# SN32F400 register map
Vendor: SONiX Technology Co., Ltd.; Series: SN32F400; File version: 1.1
CPU: CM0 r0p0, little endian, no MPU, no FPU, 2 interrupt priority bits
Registers are 32-bit, read-write, reset 0x0 unless marked. A register's access mark holds for its fields unless they carry their own. Offsets are from the block's base; [hi:lo] are bit positions.

## SN_FOC — BLDC FOC Function
Base 0x40074000
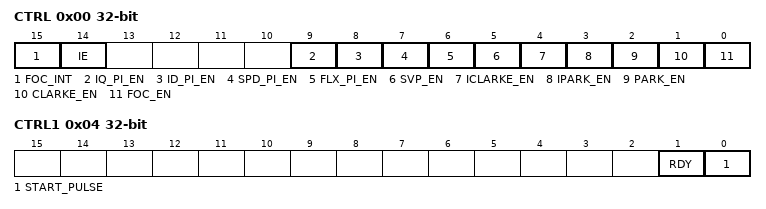
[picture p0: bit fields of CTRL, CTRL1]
0x00 CTRL — Offset:0x00 FOC Control register
  [15] FOC_INT — FOC interrupt
    0=None (No FOC interrupt); 1=Meet (FOC interrupt is triggered)
  [14] IE — FOC interrupt enable bit
    0=Disable FOC interrupt; 1=Enable FOC interrupt
  [9] IQ_PI_EN — Current Q PI function enable bit
    0=Disable current Q PI function; 1=Enable current Q PI function
  [8] ID_PI_EN — Current D PI function enable bit
    0=Disable current D PI function; 1=Enable current D PI function
  [7] SPD_PI_EN — Speed PI function enable bit
    0=Disable speed PI function; 1=Enable speed PI function
  [6] FLX_PI_EN — Flux PI function enable bit
    0=Disable flux PI function; 1=Enable flux PI function
  [5] SVP_EN — SVPWM function enable bit
    0=Disable SVPWM function; 1=Enable SVPWM function
  [4] ICLARKE_EN — IClarke function enable bit
    0=Disable IClarke function; 1=Enable IClarke function
  [3] IPARK_EN — IPark function enable bit
    0=Disable IPark function; 1=Enable IPark function
  [2] PARK_EN — Park function enable bit
    0=Disable Park function; 1=Enable Park function
  [1] CLARKE_EN — Clarke function enable bit
    0=Disable Clarke function; 1=Enable Clarke function
  [0] FOC_EN — FOC enable bit
    0=Disable FOC; 1=Enable FOC
0x04 CTRL1 — Offset:0x04 FOC Control register 1
  [1] RDY ro — FOC ready status
    0=Busy (FOC is operating); 1=Idle (FOC is not operating)
  [0] START_PULSE — FOC operation trigger bit
    0=None (No action); 1=Trigger 1 pulse to start FOC operating
0x08 IA — Offset:0x08 FOC Motor A-phase Current register
  [23:0] IA — Motor A-phase current in I24Q15 format
0x0C IB — Offset:0x0C FOC Motor B-phase Current register
  [23:0] IB — Motor B-phase current in I24Q15 format
0x10 IC — Offset:0x10 FOC Motor C-phase Current register
  [23:0] IC — Motor C-phase current in I24Q15 format
0x14 ANGLE — Offset:0x14 FOC Motor Stator Output Angle register
  [15:0] ANGLE — Motor stator output electrical angle in I24Q15 format
0x18 FLX_CMD — Offset:0x18 FOC Motor Stator Flux Command register
  [23:0] FLX_CMD — Motor stator flux command in I24Q15 format
0x1C FLX_FB — Offset:0x1C FOC Motor Stator Flux Feedback register
  [23:0] FLX_FB — Motor stator flux feedback in I24Q15 format
0x20 ID_FF — Offset:0x20 FOC D-axis Current Feedforward register
  [23:0] ID_FF — Field current D feedforward in I24Q15 format
0x24 SPD_CMD — Offset:0x24 FOC Motor Rotor Speed Command register
  [23:0] SPD_CMD — Motor rotor speed command in I24Q15 format
0x28 SPD_FB — Offset:0x28 FOC Motor Rotor Speed Feedback register
  [23:0] SPD_FB — Motor rotor speed feedback in I24Q15 format
0x2C IQ_FF — Offset:0x2C FOC Q-axis Current Feedforward register
  [23:0] IQ_FF — Torque current feedforward in I24Q15 format
0x30 ID_CMD — Offset:0x30 FOC D-axis Current Command register
  [23:0] ID_CMD — D-axis current command in I24Q15 format
0x34 VD_FF — Offset:0x34 FOC D-axis Voltage Feedforward register
  [23:0] VD_FF — D-axis voltage feedforward in I24Q15 format
0x38 IQ_CMD — Offset:0x38 FOC Q-axis Current Command register
  [23:0] IQ_CMD — Q-axis current command in I24Q15 format
0x3C VQ_FF — Offset:0x3C FOC Q-axis Voltage Feedforward register
  [23:0] VQ_FF — Q-axis voltage feedforward in I24Q15 format
0x40 SVP_RATIO reset 0x8000 — Offset:0x40 FOC SVPWM Output Ratio register
  [23:0] SVP_RATIO — SVPWM output ratio in I24Q15 format
0x44 IALFA — Offset:0x44 FOC Motor Alpha-axis Current register
  [23:0] IALFA — Motor alpha-axis current in I24Q15 format
0x48 IBETA — Offset:0x48 FOC Motor Beta-axis Current register
  [23:0] IBETA — Motor beta-axis current in I24Q15 format
0x4C ID — Offset:0x4C FOC Motor D-axis Current register
  [23:0] ID — Motor d-axis current in I24Q15 format
0x50 IQ — Offset:0x50 FOC Motor Q-axis Current register
  [23:0] IQ — Motor q-axis current in I24Q15 format
0x54 VD — Offset:0x54 FOC Driver D-axis Output Voltage register
  [23:0] VD — Driver d-axis output voltage in I24Q15 format
0x58 VQ — Offset:0x58 FOC Driver Q-axis Output Voltage register
  [23:0] VQ — Driver q-axis output voltage in I24Q15 format
0x5C VALFA — Offset:0x5C FOC Driver Alpha-axis Output Voltage register
  [23:0] VALFA — Driver alpha-axis output voltage in I24Q15 format
0x60 VBETA — Offset:0x60 FOC Driver Beta-axis Output Voltage register
  [23:0] VBETA — Driver beta-axis output voltage in I24Q15 format
0x64 VA — Offset:0x64 FOC Driver A-phase Output Voltage register
  [23:0] VA — Driver A-phase output voltage in I24Q15 format
0x68 VB — Offset:0x68 FOC Driver B-phase Output Voltage register
  [23:0] VB — Driver B-phase output voltage in I24Q15 format
0x6C VC — Offset:0x6C FOC Driver C-phase Output Voltage register
  [23:0] VC — Driver C-phase output voltage in I24Q15 format
0x70 SVP_MAX — Offset:0x70 FOC SVPWM Maximum Value register
  [23:0] SVP_MAX — Maximum value between A, B, C-phase output voltage in I24Q15 format
0x74 SVP_MIN — Offset:0x74 FOC SVPWM Minimum Value register
  [23:0] SVP_MIN — Minimum value between A, B, C-phase output voltage in I24Q15 format
0x78 SVP_DLTA — Offset:0x78 FOC SVPWM Delta Value register
  [23:0] SVP_DLTA — Difference between minimum and maximum value of SVPWM calculation in I24Q15 format
0x7C SVP_A — Offset:0x7C FOC SVPWM A-phase Output Voltage register
  [23:0] SVP_A — SVPWM A-phase output voltage in I24Q15 format
0x80 SVP_B — Offset:0x80 FOC SVPWM B-phase Output Voltage register
  [23:0] SVP_B — SVPWM B-phase output voltage in I24Q15 format
0x84 SVP_C — Offset:0x84 FOC SVPWM C-phase Output Voltage register
  [23:0] SVP_C — SVPWM C-phase output voltage in I24Q15 format
0x88 FLX_PI_KP — Offset:0x88 FOC Proportional Gain for Flux PI Controller register
  [23:0] FLX_PI_KP — Proportional gain for flux PI controller in I24Q15 format
0x8C FLX_PI_KI — Offset:0x8C FOC Integral Gain for Flux PI Controller register
  [23:0] FLX_PI_KI — Integral gain for flux PI controller in I24Q15 format
0x90 FLX_PI_MAX — Offset:0x90 FOC Maximum Output Limit for Flux PI Controller register
  [23:0] FLX_PI_MAX — Maximum output limit for flux PI controller in I24Q15 format
0x94 FLX_PI_MIN — Offset:0x94 FOC Minimum Output Limit for Flux PI Controller register
  [23:0] FLX_PI_MIN — Minimum output limit for flux PI controller in I24Q15 format
0x98 FLX_PI_CMD — Offset:0x98 FOC Command for Flux PI Controller register
  [23:0] FLX_PI_CMD — Command for flux PI controller in I24Q15 format
0x9C FLX_PI_FB — Offset:0x9C FOC Feedback for Flux PI Controller register
  [23:0] FLX_PI_FB — Feedback for flux PI controller in I24Q15 format
0xA0 FLX_PI_FF — Offset:0xA0 FOC Feedforward for Flux PI Controller register
  [23:0] FLX_PI_FF — Feedforward for flux PI controller in I24Q15 format
0xA4 FLX_PI_OUT — Offset:0xA4 FOC Output of Flux PI Controller register
  [23:0] FLX_PI_OUT — Output of flux PI controller in I24Q15 format
0xA8 FLX_PI_ERR — Offset:0xA8 FOC Error of Flux PI Controller register
  [23:0] FLX_PI_ERR — Error of flux PI controller in I24Q15 format
0xAC FLX_PI_UP — Offset:0xAC FOC Proportional Output of Flux PI Controller register
  [23:0] FLX_PI_UP — Proportional output of flux PI controller in I24Q15 format
0xB0 FLX_PI_UI — Offset:0xB0 FOC Integral Output of Flux PI Controller register
  [31:0] FLX_PI_UI — Integral output of flux PI controller in I32Q30 format
0xB4 SPD_PI_KP — Offset:0xB4 FOC Proportional Gain for Speed PI Controller register
  [23:0] SPD_PI_KP — Proportional gain for speed PI controller in I24Q15 format
0xB8 SPD_PI_KI — Offset:0xB8 FOC Integral Gain for Speed PI Controller register
  [23:0] SPD_PI_KI — Integral gain for speed PI controller in I24Q15 format
0xBC SPD_PI_MAX — Offset:0xBC FOC Maximum Output Limit for Speed PI Controller register
  [23:0] SPD_PI_MAX — Maximum output limit for speed PI controller in I24Q15 format
0xC0 SPD_PI_MIN — Offset:0xC0 FOC Minimum Output Limit for Speed PI Controller register
  [23:0] SPD_PI_MIN — Minimum output limit for speed PI controller in I24Q15 format
0xC4 SPD_PI_CMD — Offset:0xC4 FOC Command for Speed PI Controller register
  [23:0] SPD_PI_CMD — Command for speed PI controller in I24Q15 format
0xC8 SPD_PI_FB — Offset:0xC8 FOC Feedback for Speed PI Controller register
  [23:0] SPD_PI_FB — Feedback for speed PI controller in I24Q15 format
0xCC SPD_PI_FF — Offset:0xCC FOC Feedforward for Speed PI Controller register
  [23:0] SPD_PI_FF — Feedforward for speed PI controller in I24Q15 format
0xD0 SPD_PI_OUT — Offset:0xD0 FOC Output of Speed PI Controller register
  [23:0] SPD_PI_OUT — Output of speed PI controller in I24Q15 format
0xD4 SPD_PI_ERR — Offset:0xD4 FOC Error of Speed PI Controller register
  [23:0] SPD_PI_ERR — Error of speed PI controller in I24Q15 format
0xD8 SPD_PI_UP — Offset:0xD8 FOC Proportional Output of Speed PI Controller register
  [23:0] SPD_PI_UP — Proportional output of speed PI controller in I24Q15 format
0xDC SPD_PI_UI — Offset:0xDC FOC Integral Output of Speed PI Controller register
  [31:0] SPD_PI_UI — Integral output of speed PI controller in I32Q30 format
0xE0 ID_PI_KP — Offset:0xE0 FOC Proportional Gain for D-axis Current PI Controller register
  [23:0] ID_PI_KP — Proportional gain for d-axis current PI controller in I24Q15 format
0xE4 ID_PI_KI — Offset:0xE4 FOC Integral Gain for D-axis Current PI Controller register
  [23:0] ID_PI_KI — Integral gain for d-axis current PI controller in I24Q15 format
0xE8 ID_PI_MAX — Offset:0xE8 FOC Maximum Output Limit for D-axis Current PI Controller register
  [23:0] ID_PI_MAX — Maximum output limit for d-axis current PI controller in I24Q15 format
0xEC ID_PI_MIN — Offset:0xEC FOC Minimum Output Limit for D-axis Current PI Controller register
  [23:0] ID_PI_MIN — Minimum output limit for d-axis current PI controller in I24Q15 format
0xF0 ID_PI_CMD — Offset:0xF0 FOC Command for D-axis Current PI Controller register
  [23:0] ID_PI_CMD — Command for d-axis current PI controller in I24Q15 format
0xF4 ID_PI_FB — Offset:0xF4 FOC Feedback for D-axis Current PI Controller register
  [23:0] ID_PI_FB — Feedback for d-axis current PI controller in I24Q15 format
0xF8 ID_PI_FF — Offset:0xF8 FOC Feedforward for D-axis Current PI Controller register
  [23:0] ID_PI_FF — Feedforward for d-axis current PI controller in I24Q15 format
0xFC ID_PI_OUT — Offset:0xFC FOC Output of D-axis Current PI Controller register
  [23:0] ID_PI_OUT — Output of d-axis current PI controller in I24Q15 format
0x100 ID_PI_ERR — Offset:0x100 FOC Error of D-axis Current PI Controller register
  [23:0] ID_PI_ERR — Error of d-axis current PI controller in I24Q15 format
0x104 ID_PI_UP — Offset:0x104 FOC Proportional Output of D-axis Current PI Controller register
  [23:0] ID_PI_UP — Proportional output of d-axis current PI controller in I24Q15 format
0x108 ID_PI_UI — Offset:0x108 FOC Integral Output of D-axis Current PI Controller register
  [31:0] ID_PI_UI — Integral output of d-axis current PI controller in I32Q30 format
0x10C IQ_PI_KP — Offset:0x10C FOC Proportional gain for Q-axis Current PI Controller register
  [23:0] IQ_PI_KP — Proportional gain for q-axis current PI controller in I24Q15 format
0x110 IQ_PI_KI — Offset:0x110 FOC Integral gain for Q-axis Current PI Controller register
  [23:0] IQ_PI_KI — Integral gain for q-axis current PI controller in I24Q15 format
0x114 IQ_PI_MAX — Offset:0x114 FOC Maximum Output Limit for Q-axis Current PI Controller register
  [23:0] IQ_PI_MAX — Maximum output limit for q-axis current PI controller in I24Q15 format
0x118 IQ_PI_MIN — Offset:0x118 FOC Minimum Output Limit for Q-axis Current PI Controller register
  [23:0] IQ_PI_MIN — Minimum output limit for q-axis current PI controller in I24Q15 format
0x11C IQ_PI_CMD — Offset:0x11C FOC Command for Q-axis Current PI Controller register
  [23:0] IQ_PI_CMD — Command for q-axis current PI controller in I24Q15 format
0x120 IQ_PI_FB — Offset:0x120 FOC Feedback for Q-axis Current PI Controller register
  [23:0] IQ_PI_FB — Feedback for q-axis current PI controller in I24Q15 format
0x124 IQ_PI_FF — Offset:0x124 FOC Feedforward for Q-axis Current PI Controller register
  [23:0] IQ_PI_FF — Feedforward for q-axis current PI controller in I24Q15 format
0x128 IQ_PI_OUT — Offset:0x128 FOC Output of Q-axis Current PI Controller register
  [23:0] IQ_PI_OUT — Output of q-axis current PI controller in I24Q15 format
0x12C IQ_PI_ERR — Offset:0x12C FOC Error of Q-axis Current PI Controller register
  [23:0] IQ_PI_ERR — Error of q-axis current PI controller in I24Q15 format
0x130 IQ_PI_UP — Offset:0x130 FOC Proportional Output of Q-axis Current PI Controller register
  [23:0] IQ_PI_UP — Proportional output of q-axis current PI controller in I24Q15 format
0x134 IQ_PI_UI — Offset:0x134 FOC Integral Outputof Q-axis Current PI Controller register
  [31:0] IQ_PI_UI — Integral output of q-axis current PI controller in I32Q30 format
